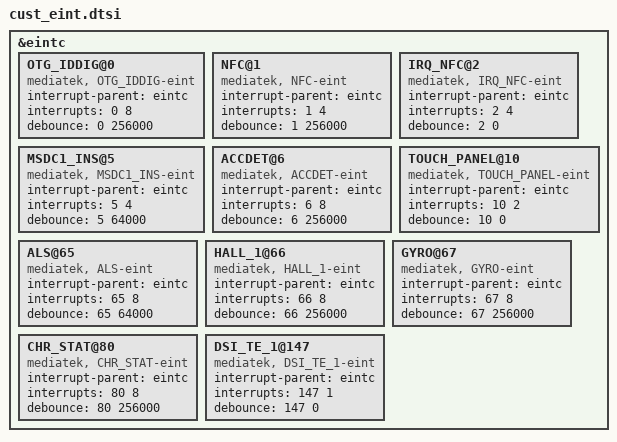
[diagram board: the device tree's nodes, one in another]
/*
 * Generated by MTK SP DrvGen Version 03.13.6 for MT6753. Copyright MediaTek Inc. (C) 2013.
 * Thu Sep 17 14:09:56 2015
 * Do Not Modify the File.
 */

/*************************
 * EINT DTSI File
*************************/

&eintc {
	OTG_IDDIG@0 {
		compatible = "mediatek, OTG_IDDIG-eint";
		interrupt-parent = <&eintc>;
		interrupts = <0 8>;
		debounce = <0 256000>;
	};

	NFC@1 {
		compatible = "mediatek, NFC-eint";
		interrupt-parent = <&eintc>;
		interrupts = <1 4>;
		debounce = <1 256000>;
	};

	IRQ_NFC@2 {
		compatible = "mediatek, IRQ_NFC-eint";
		interrupt-parent = <&eintc>;
		interrupts = <2 4>;
		debounce = <2 0>;
	};

	MSDC1_INS@5 {
		compatible = "mediatek, MSDC1_INS-eint";
		interrupt-parent = <&eintc>;
		interrupts = <5 4>;
		debounce = <5 64000>;
	};

	ACCDET@6 {
		compatible = "mediatek, ACCDET-eint";
		interrupt-parent = <&eintc>;
		interrupts = <6 8>;
		debounce = <6 256000>;
	};

	TOUCH_PANEL@10 {
		compatible = "mediatek, TOUCH_PANEL-eint";
		interrupt-parent = <&eintc>;
		interrupts = <10 2>;
		debounce = <10 0>;
	};

	ALS@65 {
		compatible = "mediatek, ALS-eint";
		interrupt-parent = <&eintc>;
		interrupts = <65 8>;
		debounce = <65 64000>;
	};

	HALL_1@66 {
		compatible = "mediatek, HALL_1-eint";
		interrupt-parent = <&eintc>;
		interrupts = <66 8>;
		debounce = <66 256000>;
	};

	GYRO@67 {
		compatible = "mediatek, GYRO-eint";
		interrupt-parent = <&eintc>;
		interrupts = <67 8>;
		debounce = <67 256000>;
	};

	CHR_STAT@80 {
		compatible = "mediatek, CHR_STAT-eint";
		interrupt-parent = <&eintc>;
		interrupts = <80 8>;
		debounce = <80 256000>;
	};

	DSI_TE_1@147 {
		compatible = "mediatek, DSI_TE_1-eint";
		interrupt-parent = <&eintc>;
		interrupts = <147 1>;
		debounce = <147 0>;
	};

};
